# DECODER0_MSVDX_VDMC register map
Vendor: Texas Instruments
Peripheral module from a debugger description file (folder J7ES).
Registers are 32-bit, read-only, reset 0x0 unless marked. A register's access mark holds for its fields unless they carry their own. Offsets are as the file gives them; lines under a group give offsets from that group; [hi:lo] are bit positions; {n}, {i} and the like mark numbered series; 'fields as' and 'values as' point back to an identical list; <NAME> marks a mode.

## DECODER0_MSVDX_VDMC
0x00 DECODER0_CR_VDMC_REFERENCE_CACHE_SIGNATURE
  [31:0] CR_VDMC_REFCACHE_SIG — VDMC reference cache signature analysis output.
0x04 DECODER0_CR_VDMC_REFERENCE_CACHE_EFFICIENCY
  [31:0] CR_VDMC_REFCACHE_EFFICIENCY — VDMC reference cache efficiency.
0x08 DECODER0_CR_VDMC_2D_FILTER_PIPELINE_SIGNATURE
  [31:0] CR_VDMC_FILT_SIG — VDMC 2D filter pipeline signature analysis output.
0x0C DECODER0_CR_VDMC_PIXEL_RECONSTRUCTION_SIGNATURE
  [31:0] CR_VDMC_RECON_SIG — VDMC pixel reconstruction signature analysis output.
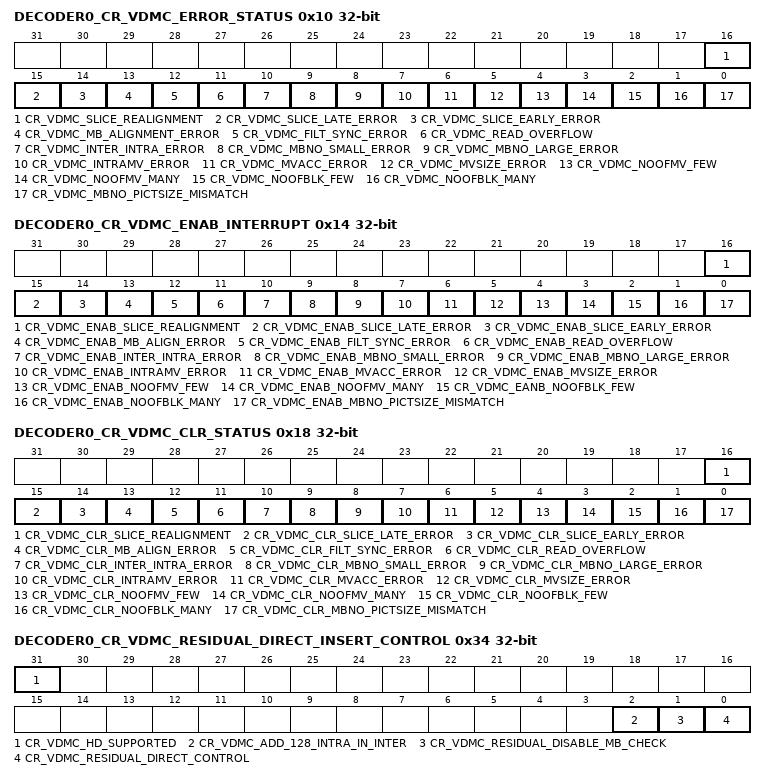
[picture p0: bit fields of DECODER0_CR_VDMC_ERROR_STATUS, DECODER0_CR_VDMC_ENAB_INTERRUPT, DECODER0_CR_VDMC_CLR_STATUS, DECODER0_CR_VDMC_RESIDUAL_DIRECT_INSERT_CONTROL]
0x10 DECODER0_CR_VDMC_ERROR_STATUS
  [16] CR_VDMC_SLICE_REALIGNMENT — VDMC residual slice boundary re-aligned to command bus slice boundary
  [15] CR_VDMC_SLICE_LATE_ERROR — VDMC residual slice boundary flag not set when command bus indicated slice boundary
  [14] CR_VDMC_SLICE_EARLY_ERROR — VDMC residual slice boundary flag set when command bus indicated more residual data in slice
  [13] CR_VDMC_MB_ALIGNMENT_ERROR — VDMC residual interface macroblock boundary does not match expected residual macroblock boundary
  [12] CR_VDMC_FILT_SYNC_ERROR — VDMC 2D filter intra and inter paths out-of-sync
  [11] CR_VDMC_READ_OVERFLOW — VDMC reference cache read buffer overflow
  [10] CR_VDMC_INTER_INTRA_ERROR — VDMC intra and inter commands for the same block
  [9] CR_VDMC_MBNO_SMALL_ERROR — VDMC expected macroblock number from VEC is too small
  [8] CR_VDMC_MBNO_LARGE_ERROR — VDMC expected macroblock number from VEC is too large
  [7] CR_VDMC_INTRAMV_ERROR — VDMC motion vector with an intra block
  [6] CR_VDMC_MVACC_ERROR — VDMC 1/
  [5] CR_VDMC_MVSIZE_ERROR — VDMC smaller motion vector than 8x8 in non H.264 streams
  [4] CR_VDMC_NOOFMV_FEW — VDMC too few motion vectors per block
  [3] CR_VDMC_NOOFMV_MANY — VDMC too many motion vectors per block
  [2] CR_VDMC_NOOFBLK_FEW — VDMC too few block predictions per block
  [1] CR_VDMC_NOOFBLK_MANY — VDMC too many block predictions per block
  [0] CR_VDMC_MBNO_PICTSIZE_MISMATCH — VDMC macroblock number and picture size mismatch
0x14 DECODER0_CR_VDMC_ENAB_INTERRUPT rw
  [16] CR_VDMC_ENAB_SLICE_REALIGNMENT — Write '1' to enable interrupt for residual slice boundary re-aligned
  [15] CR_VDMC_ENAB_SLICE_LATE_ERROR — Write '1' to enable interrupt for residual slice boundary late flag
  [14] CR_VDMC_ENAB_SLICE_EARLY_ERROR — Write '1' to enable interrupt for residual slice boundary early flag
  [13] CR_VDMC_ENAB_MB_ALIGN_ERROR — Write '1' to enable interrupt for residual macroblock miss-alignment flag
  [12] CR_VDMC_ENAB_FILT_SYNC_ERROR — Write '1' to enable interrupt for 2D filter intra and inter paths out-of-sync
  [11] CR_VDMC_ENAB_READ_OVERFLOW — Write '1' to enable interrupt for reference cache read buffer overflow
  [10] CR_VDMC_ENAB_INTER_INTRA_ERROR — Write '1' to enable interrupt for intra and inter commands for the same block
  [9] CR_VDMC_ENAB_MBNO_SMALL_ERROR — Write '1' to enable interrupt for expected macroblock number from VEC is too small
  [8] CR_VDMC_ENAB_MBNO_LARGE_ERROR — Write '1' to enable interrupt for expected macroblock number from VEC is too large
  [7] CR_VDMC_ENAB_INTRAMV_ERROR — Write '1' to enable interrupt for motion vector with an intra block
  [6] CR_VDMC_ENAB_MVACC_ERROR — Write '1' to enable interrupt for 1/
  [5] CR_VDMC_ENAB_MVSIZE_ERROR — Write '1' to enable interrupt for smaller motion vector than 8x8 in non H.264 streams
  [4] CR_VDMC_ENAB_NOOFMV_FEW — Write '1' to enable interrupt for too few motion vectors per block
  [3] CR_VDMC_ENAB_NOOFMV_MANY — Write '1' to enable interrupt for too many motion vectors per block
  [2] CR_VDMC_EANB_NOOFBLK_FEW — Write '1' to enable interrupt for too few block predictions per block
  [1] CR_VDMC_ENAB_NOOFBLK_MANY — Write '1' to enable interrupt for too many block predictions per block
  [0] CR_VDMC_ENAB_MBNO_PICTSIZE_MISMATCH — Write '1' to enable interrupt for macroblock number and picture size mismatch
0x18 DECODER0_CR_VDMC_CLR_STATUS wo
  [16] CR_VDMC_CLR_SLICE_REALIGNMENT — Write '1' to clear status for residual slice boundary re-aligned
  [15] CR_VDMC_CLR_SLICE_LATE_ERROR — Write '1' to clear status for residual slice boundary late flag
  [14] CR_VDMC_CLR_SLICE_EARLY_ERROR — Write '1' to clear status for residual slice boundary early flag
  [13] CR_VDMC_CLR_MB_ALIGN_ERROR — Write '1' to clear status for residual macroblock miss-alignment flag
  [12] CR_VDMC_CLR_FILT_SYNC_ERROR — Write '1' to clear status for 2D filter intra and inter paths out-of-sync
  [11] CR_VDMC_CLR_READ_OVERFLOW — Write '1' to clear status for reference cache read buffer overflow
  [10] CR_VDMC_CLR_INTER_INTRA_ERROR — Write '1' to clear status for intra and inter commands for the same block
  [9] CR_VDMC_CLR_MBNO_SMALL_ERROR — Write '1' to clear status for expected macroblock number from VEC is too small
  [8] CR_VDMC_CLR_MBNO_LARGE_ERROR — Write '1' to clear status for expected macroblock number from VEC is too large
  [7] CR_VDMC_CLR_INTRAMV_ERROR — Write '1' to clear status for motion vector with an Intra block
  [6] CR_VDMC_CLR_MVACC_ERROR — Write '1' to clear status for 1/
  [5] CR_VDMC_CLR_MVSIZE_ERROR — Write '1' to clear status for smaller motion vector than 8x8 in non H.264 streams
  [4] CR_VDMC_CLR_NOOFMV_FEW — Write '1' to clear status for too few motion vectors per block
  [3] CR_VDMC_CLR_NOOFMV_MANY — Write '1' to clear status for too many motion vectors per block
  [2] CR_VDMC_CLR_NOOFBLK_FEW — Write '1' to clear status for too few block predictions per block
  [1] CR_VDMC_CLR_NOOFBLK_MANY — Write '1' to clear status for too many block predictions per block
  [0] CR_VDMC_CLR_MBNO_PICTSIZE_MISMATCH — Write '1' to clear status for macroblock number and picture size mismatch
0x20 DECODER0_CR_VDMC_2D_FILTER_PIPELINE_DIRECT_INSERT_DATA rw
  [31:0] CR_VDMC_FILT_DIRECT_DATA — VDMC 2D filter pipeline direct insert data.
0x24 DECODER0_CR_VDMC_2D_FILTER_PIPELINE_DIRECT_INSERT_CONTROL rw
  [31:0] CR_VDMC_FILT_DIRECT_CONTROL — VDMC 2D filter pipeline direct insert control.
0x28 DECODER0_CR_VDMC_PIXEL_RECONSTRUCTION_DIRECT_INSERT_DATA rw
  [31:0] CR_VDMC_RECON_DIRECT_DATA — VDMC pixel reconstruction direct insert data.
0x2C DECODER0_CR_VDMC_PIXEL_RECONSTRUCTION_DIRECT_INSERT_CONTROL rw
  [14:0] CR_VDMC_RECON_DIRECT_CONTROL — VDMC pixel reconstruction direct insert control.
0x30 DECODER0_CR_VDMC_RESIDUAL_DIRECT_INSERT_DATA rw
  [31:0] CR_VDMC_RESIDUAL_DIRECT_DATA — VDMC residual direct insert data.
0x34 DECODER0_CR_VDMC_RESIDUAL_DIRECT_INSERT_CONTROL rw
  [31] CR_VDMC_HD_SUPPORTED
  [2] CR_VDMC_ADD_128_INTRA_IN_INTER — In the case of intra prediction tiles within inter MB [i.e.
  [1] CR_VDMC_RESIDUAL_DISABLE_MB_CHECK — VDMC residual disable macroblock alignment check.
  [0] CR_VDMC_RESIDUAL_DIRECT_CONTROL — VDMC residual direct insert control.
0x40 DECODER0_CR_VDMC_LUMA_ERROR_BASE_ADDR rw
  [31:6] CR_VDMC_LUMA_ERROR_BASE — VDMC luma base addr
0x44 DECODER0_CR_VDMC_CHROMA_ERROR_BASE_ADDR rw
  [31:6] CR_VDMC_CHROMA_ERROR_BASE — VDMC chroma base addr
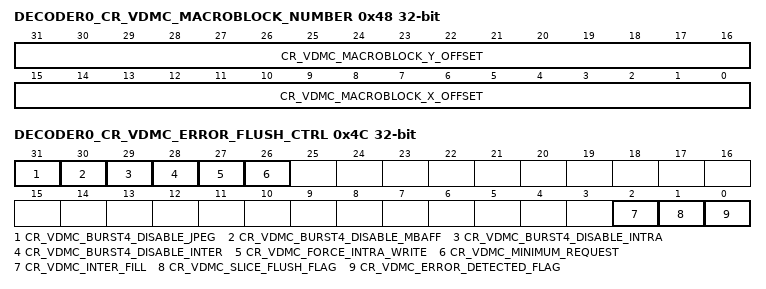
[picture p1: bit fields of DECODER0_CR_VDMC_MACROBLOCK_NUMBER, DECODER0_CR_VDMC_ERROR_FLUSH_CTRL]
0x48 DECODER0_CR_VDMC_MACROBLOCK_NUMBER
  [31:16] CR_VDMC_MACROBLOCK_Y_OFFSET — VDMC vertical offset of macroblock at input to pixel reconstruction unit
  [15:0] CR_VDMC_MACROBLOCK_X_OFFSET — VDMC horizontal offset of macroblock at input to pixel reconstruction unit
0x4C DECODER0_CR_VDMC_ERROR_FLUSH_CTRL rw
  [31] CR_VDMC_BURST4_DISABLE_JPEG — when set this bit will disable burst4 accesses for jpeg cache writes
  [30] CR_VDMC_BURST4_DISABLE_MBAFF — when set this bit will disable burst4 accesses for intra mbaff cache reads
  [29] CR_VDMC_BURST4_DISABLE_INTRA — when set this bit will disable burst4 accesses for intra cache reads
  [28] CR_VDMC_BURST4_DISABLE_INTER — when set this bit will disable burst4 accesses for inter cache reads
  [27] CR_VDMC_FORCE_INTRA_WRITE — when set this bit will force all above intra data to be written to the intra buffer
  [26] CR_VDMC_MINIMUM_REQUEST — when set this bit will only request the data it requires
  [2] CR_VDMC_INTER_FILL — If the error detected flag is set, and this flag is 1, zero motion P macroblocks relative to LUMA/CHROMA_ERROR_BASE_ADDR will be output.
  [1] CR_VDMC_SLICE_FLUSH_FLAG — Slice flush flag set to indicate VDMC input should be flushed to next slice boundary [no zero motion vector output blocks will be generated].
  [0] CR_VDMC_ERROR_DETECTED_FLAG — Error detected flag set to indicate VDMC input should be flushed to next slice boundary, and zero motion vector P macroblocks should be output.
0x50 DECODER0_CR_VDMC_MCU_SIGNATURE
  [31:0] CR_VDMC_MCU_SIG — VDMC MCU signature analysis output.
0x54 DECODER0_CR_VDMC_RES_BUFFER_WRITES
  [31:0] CR_VDMC_RES_WRITES — VDMC residual buffer write space.
0x58 DECODER0_CR_VDMC_REFERENCE_CACHE_MEM_WADDR_SIGNATURE
  [31:0] CR_VDMC_REFCACHE_MEM_WADDR_SIG — VDMC reference cache memory write address signature analysis output.
0x5C DECODER0_CR_VDMC_REFERENCE_CACHE_MEM_RADDR_SIGNATURE
  [31:0] CR_VDMC_REFCACHE_MEM_RADDR_SIG — VDMC reference cache memory read address signature analysis output.
0x60 DECODER0_CR_VDMC_REFERENCE_CACHE_MEM_WDATA_SIGNATURE
  [31:0] CR_VDMC_REFCACHE_MEM_WDATA_SIG — VDMC reference cache memory write data signature analysis output.
0x64 DECODER0_CR_VDMC_REFERENCE_CACHE_MEM_RDATA_SIGNATURE
  [31:0] CR_VDMC_REFCACHE_MEM_RDATA_SIG — VDMC reference cache memory read data signature analysis output.
0x68 DECODER0_CR_VDMC_REFERENCE_CACHE_MEM_PRELOAD_SIGNATURE
  [31:0] CR_VDMC_REFCACHE_MEM_PRELOAD_SIG — VDMC reference cache memory preload data signature analysis output.
